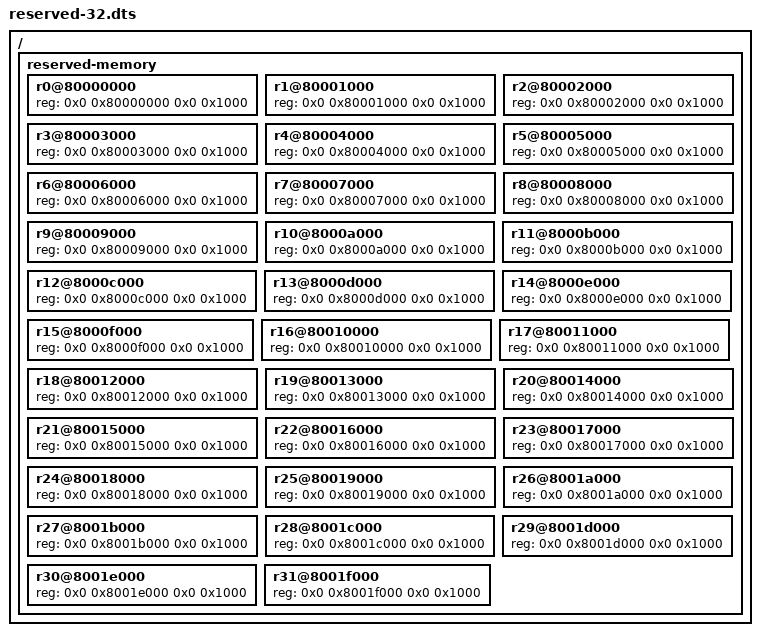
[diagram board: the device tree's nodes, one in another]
/dts-v1/;

/ {
	#address-cells = <2>;
	#size-cells = <2>;

	reserved-memory {
		#address-cells = <2>;
		#size-cells = <2>;
		ranges;

		r0@80000000 {
			reg = <0x0 0x80000000 0x0 0x1000>;
		};

		r1@80001000 {
			reg = <0x0 0x80001000 0x0 0x1000>;
		};

		r2@80002000 {
			reg = <0x0 0x80002000 0x0 0x1000>;
		};

		r3@80003000 {
			reg = <0x0 0x80003000 0x0 0x1000>;
		};

		r4@80004000 {
			reg = <0x0 0x80004000 0x0 0x1000>;
		};

		r5@80005000 {
			reg = <0x0 0x80005000 0x0 0x1000>;
		};

		r6@80006000 {
			reg = <0x0 0x80006000 0x0 0x1000>;
		};

		r7@80007000 {
			reg = <0x0 0x80007000 0x0 0x1000>;
		};

		r8@80008000 {
			reg = <0x0 0x80008000 0x0 0x1000>;
		};

		r9@80009000 {
			reg = <0x0 0x80009000 0x0 0x1000>;
		};

		r10@8000a000 {
			reg = <0x0 0x8000a000 0x0 0x1000>;
		};

		r11@8000b000 {
			reg = <0x0 0x8000b000 0x0 0x1000>;
		};

		r12@8000c000 {
			reg = <0x0 0x8000c000 0x0 0x1000>;
		};

		r13@8000d000 {
			reg = <0x0 0x8000d000 0x0 0x1000>;
		};

		r14@8000e000 {
			reg = <0x0 0x8000e000 0x0 0x1000>;
		};

		r15@8000f000 {
			reg = <0x0 0x8000f000 0x0 0x1000>;
		};

		r16@80010000 {
			reg = <0x0 0x80010000 0x0 0x1000>;
		};

		r17@80011000 {
			reg = <0x0 0x80011000 0x0 0x1000>;
		};

		r18@80012000 {
			reg = <0x0 0x80012000 0x0 0x1000>;
		};

		r19@80013000 {
			reg = <0x0 0x80013000 0x0 0x1000>;
		};

		r20@80014000 {
			reg = <0x0 0x80014000 0x0 0x1000>;
		};

		r21@80015000 {
			reg = <0x0 0x80015000 0x0 0x1000>;
		};

		r22@80016000 {
			reg = <0x0 0x80016000 0x0 0x1000>;
		};

		r23@80017000 {
			reg = <0x0 0x80017000 0x0 0x1000>;
		};

		r24@80018000 {
			reg = <0x0 0x80018000 0x0 0x1000>;
		};

		r25@80019000 {
			reg = <0x0 0x80019000 0x0 0x1000>;
		};

		r26@8001a000 {
			reg = <0x0 0x8001a000 0x0 0x1000>;
		};

		r27@8001b000 {
			reg = <0x0 0x8001b000 0x0 0x1000>;
		};

		r28@8001c000 {
			reg = <0x0 0x8001c000 0x0 0x1000>;
		};

		r29@8001d000 {
			reg = <0x0 0x8001d000 0x0 0x1000>;
		};

		r30@8001e000 {
			reg = <0x0 0x8001e000 0x0 0x1000>;
		};

		r31@8001f000 {
			reg = <0x0 0x8001f000 0x0 0x1000>;
		};

	};
};
